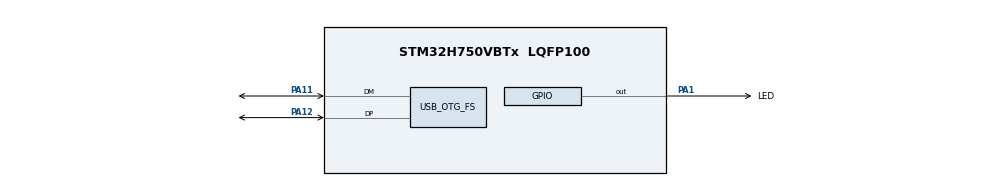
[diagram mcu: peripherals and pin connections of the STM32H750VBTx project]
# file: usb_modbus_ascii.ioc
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Mcu.Family=STM32H7
Mcu.Name=STM32H750VBTx
Mcu.Package=LQFP100
NVIC.OTG_FS_IRQn=true\:0\:0\:false\:false\:true\:false\:true\:true
NVIC.PriorityGroup=NVIC_PRIORITYGROUP_4
NVIC.TIM17_IRQn=true\:15\:0\:false\:false\:true\:false\:true\:true
NVIC.TIM2_IRQn=true\:0\:0\:false\:false\:true\:true\:true\:true
NVIC.TimeBase=TIM17_IRQn
NVIC.TimeBaseIP=TIM17
PA1.GPIO_Label=LED
PA1.PinState=GPIO_PIN_SET
PA1.Signal=GPIO_Output
PA11.Mode=Device_Only
PA11.Signal=USB_OTG_FS_DM
PA12.Mode=Device_Only
PA12.Signal=USB_OTG_FS_DP
PA13\ (JTMS/SWDIO).Mode=Serial_Wire
PA13\ (JTMS/SWDIO).Signal=DEBUG_JTMS-SWDIO
PA14\ (JTCK/SWCLK).Mode=Serial_Wire
PA14\ (JTCK/SWCLK).Signal=DEBUG_JTCK-SWCLK
PH0-OSC_IN\ (PH0).Mode=HSE-External-Oscillator
PH0-OSC_IN\ (PH0).Signal=RCC_OSC_IN
PH1-OSC_OUT\ (PH1).Mode=HSE-External-Oscillator
PH1-OSC_OUT\ (PH1).Signal=RCC_OSC_OUT
ProjectManager.HeapSize=0x200
ProjectManager.StackSize=0x400
ProjectManager.TargetToolchain=STM32CubeIDE
RCC.ADCFreq_Value=40000000
RCC.APB1Freq_Value=100000000
RCC.APB2Freq_Value=100000000
RCC.APB3Freq_Value=100000000
RCC.APB4Freq_Value=100000000
RCC.CortexFreq_Value=200000000
RCC.D1PPRE=RCC_APB3_DIV2
RCC.D2PPRE1=RCC_APB1_DIV2
RCC.D2PPRE2=RCC_APB2_DIV2
RCC.D3PPRE=RCC_APB4_DIV2
RCC.DIVM1=2
RCC.DIVM2=25
RCC.DIVM3=2
RCC.DIVN1=32
RCC.DIVN2=160
RCC.DIVN3=12
RCC.DIVP2=4
RCC.DIVQ3=3
RCC.HCLKFreq_Value=200000000
RCC.PLL3FRACN=0
RCC.PLLFRACN=0
RCC.PLLSourceVirtual=RCC_PLLSOURCE_HSE
RCC.SYSCLKFreq_VALUE=200000000
RCC.SYSCLKSource=RCC_SYSCLKSOURCE_PLLCLK
RCC.USBCLockSelection=RCC_USBCLKSOURCE_PLL3
RCC.USBFreq_Value=50000000
TIM2.Period=1999
TIM2.Prescaler=199
USB_DEVICE.CLASS_NAME_FS=CDC
USB_DEVICE.VirtualMode-CDC_FS=Cdc
USB_DEVICE.VirtualModeFS=Cdc_FS
USB_OTG_FS.VirtualMode=Device_Only
VP_SYS_VS_tim17.Mode=TIM17
VP_TIM2_VS_ClockSourceINT.Mode=Internal
VP_USB_DEVICE_VS_USB_DEVICE_CDC_FS.Mode=CDC_FS
board=custom

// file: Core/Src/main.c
/* USER CODE BEGIN Header */
/**
  ******************************************************************************
  * @file           : main.c
  * @brief          : Main program body
  ******************************************************************************
  * @attention
  *
  * Copyright (c) 2024 STMicroelectronics.
  * All rights reserved.
  *
  * This software is licensed under terms that can be found in the LICENSE file
  * in the root directory of this software component.
  * If no LICENSE file comes with this software, it is provided AS-IS.
  *
  ******************************************************************************
  */
/* USER CODE END Header */
#include "main.h"
#include "usb_device.h"

/* USER CODE BEGIN Includes */
#include <stdio.h>
#include "use.h"
/* USER CODE END Includes */

TIM_HandleTypeDef htim2;

void SystemClock_Config(void);
static void MX_GPIO_Init(void);
static void MX_TIM2_Init(void);

int main(void)
{

  /* MCU Configuration--------------------------------------------------------*/

  /* Reset of all peripherals, Initializes the Flash interface and the Systick. */
  HAL_Init();

  /* Configure the system clock */
  SystemClock_Config();

  /* Initialize all configured peripherals */
  MX_GPIO_Init();
  MX_USB_DEVICE_Init();
  MX_TIM2_Init();
  /* USER CODE BEGIN 2 */
  setup();
  /* USER CODE END 2 */

  /* Infinite loop */
  while (1)
  {

    /* USER CODE BEGIN 3 */
	  loop();
  }
  /* USER CODE END 3 */
}

void SystemClock_Config(void)
{
  RCC_OscInitTypeDef RCC_OscInitStruct = {0};
  RCC_ClkInitTypeDef RCC_ClkInitStruct = {0};

  /** Supply configuration update enable
  */
  HAL_PWREx_ConfigSupply(PWR_LDO_SUPPLY);

  /** Configure the main internal regulator output voltage
  */
  __HAL_PWR_VOLTAGESCALING_CONFIG(PWR_REGULATOR_VOLTAGE_SCALE3);

  while(!__HAL_PWR_GET_FLAG(PWR_FLAG_VOSRDY)) {}

  /** Initializes the RCC Oscillators according to the specified parameters
  * in the RCC_OscInitTypeDef structure.
  */
  RCC_OscInitStruct.OscillatorType = RCC_OSCILLATORTYPE_HSE;
  RCC_OscInitStruct.HSEState = RCC_HSE_ON;
  RCC_OscInitStruct.PLL.PLLState = RCC_PLL_ON;
  RCC_OscInitStruct.PLL.PLLSource = RCC_PLLSOURCE_HSE;
  RCC_OscInitStruct.PLL.PLLM = 2;
  RCC_OscInitStruct.PLL.PLLN = 32;
  RCC_OscInitStruct.PLL.PLLP = 2;
  RCC_OscInitStruct.PLL.PLLQ = 2;
  RCC_OscInitStruct.PLL.PLLR = 2;
  RCC_OscInitStruct.PLL.PLLRGE = RCC_PLL1VCIRANGE_3;
  RCC_OscInitStruct.PLL.PLLVCOSEL = RCC_PLL1VCOWIDE;
  RCC_OscInitStruct.PLL.PLLFRACN = 0;
  if (HAL_RCC_OscConfig(&RCC_OscInitStruct) != HAL_OK)
  {
    Error_Handler();
  }

  /** Initializes the CPU, AHB and APB buses clocks
  */
  RCC_ClkInitStruct.ClockType = RCC_CLOCKTYPE_HCLK|RCC_CLOCKTYPE_SYSCLK
                              |RCC_CLOCKTYPE_PCLK1|RCC_CLOCKTYPE_PCLK2
                              |RCC_CLOCKTYPE_D3PCLK1|RCC_CLOCKTYPE_D1PCLK1;
  RCC_ClkInitStruct.SYSCLKSource = RCC_SYSCLKSOURCE_PLLCLK;
  RCC_ClkInitStruct.SYSCLKDivider = RCC_SYSCLK_DIV1;
  RCC_ClkInitStruct.AHBCLKDivider = RCC_HCLK_DIV1;
  RCC_ClkInitStruct.APB3CLKDivider = RCC_APB3_DIV2;
  RCC_ClkInitStruct.APB1CLKDivider = RCC_APB1_DIV2;
  RCC_ClkInitStruct.APB2CLKDivider = RCC_APB2_DIV2;
  RCC_ClkInitStruct.APB4CLKDivider = RCC_APB4_DIV2;

  if (HAL_RCC_ClockConfig(&RCC_ClkInitStruct, FLASH_LATENCY_4) != HAL_OK)
  {
    Error_Handler();
  }
}

static void MX_TIM2_Init(void)
{

  TIM_ClockConfigTypeDef sClockSourceConfig = {0};
  TIM_MasterConfigTypeDef sMasterConfig = {0};

  htim2.Instance = TIM2;
  htim2.Init.Prescaler = 199;
  htim2.Init.CounterMode = TIM_COUNTERMODE_UP;
  htim2.Init.Period = 1999;
  htim2.Init.ClockDivision = TIM_CLOCKDIVISION_DIV1;
  htim2.Init.AutoReloadPreload = TIM_AUTORELOAD_PRELOAD_DISABLE;
  if (HAL_TIM_Base_Init(&htim2) != HAL_OK)
  {
    Error_Handler();
  }
  sClockSourceConfig.ClockSource = TIM_CLOCKSOURCE_INTERNAL;
  if (HAL_TIM_ConfigClockSource(&htim2, &sClockSourceConfig) != HAL_OK)
  {
    Error_Handler();
  }
  sMasterConfig.MasterOutputTrigger = TIM_TRGO_RESET;
  sMasterConfig.MasterSlaveMode = TIM_MASTERSLAVEMODE_DISABLE;
  if (HAL_TIMEx_MasterConfigSynchronization(&htim2, &sMasterConfig) != HAL_OK)
  {
    Error_Handler();
  }

}

static void MX_GPIO_Init(void)
{
  GPIO_InitTypeDef GPIO_InitStruct = {0};

  /* GPIO Ports Clock Enable */
  __HAL_RCC_GPIOH_CLK_ENABLE();
  __HAL_RCC_GPIOA_CLK_ENABLE();

  /*Configure GPIO pin Output Level */
  HAL_GPIO_WritePin(LED_GPIO_Port, LED_Pin, GPIO_PIN_SET);

  /*Configure GPIO pin : LED_Pin */
  GPIO_InitStruct.Pin = LED_Pin;
  GPIO_InitStruct.Mode = GPIO_MODE_OUTPUT_PP;
  GPIO_InitStruct.Pull = GPIO_NOPULL;
  GPIO_InitStruct.Speed = GPIO_SPEED_FREQ_LOW;
  HAL_GPIO_Init(LED_GPIO_Port, &GPIO_InitStruct);

}

void HAL_TIM_PeriodElapsedCallback(TIM_HandleTypeDef *htim)
{
  /* USER CODE BEGIN Callback 0 */
	if (htim->Instance == TIM2) {
		upload_data();
	}
  /* USER CODE END Callback 0 */
  if (htim->Instance == TIM17) {
    HAL_IncTick();
  }
}

void Error_Handler(void)
{
  __disable_irq();
  while (1)
  {
  }
}
